# CY8C3866PVI_021 register map
File version: 0.1
CY8C38
Registers are 8-bit, read-write, no defined reset value unless marked. A register's access mark holds for its fields unless they carry their own. Offsets are from the block's base; lines under a group give offsets from that group; [hi:lo] are bit positions; {n}, {i} and the like mark numbered series; 'fields as' and 'values as' point back to an identical list; <NAME> marks a mode.

## Memory map
0x00004394 USBUART_1 size 0x1D0A — USBFS
0x000043A3 PWM_Rud size 0xB7C
0x000043A3 PWM_Bag size 0xB64
0x000043A3 PWM_Elv size 0xB70
0x000043A3 PWM_Thr size 0xB88
0x000049C8 I2C size 0x15
0x00006400 Counter_Thr size 0x92
0x00006402 Counter_Elv size 0x92
0x00006404 Counter_Rud size 0x92
0x00006406 Counter_Mod size 0x92
0x00006408 Counter_Bag size 0x92
0x00006504 Timer_Global size 0x94

## PWM_Rud
Base 0x000043A3
0x00 PWM_Rud_GLOBAL_ENABLE — PM.ACT.CFG
  [3:0] en_timer — Enable timer/counters.
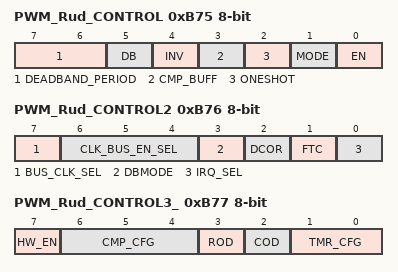
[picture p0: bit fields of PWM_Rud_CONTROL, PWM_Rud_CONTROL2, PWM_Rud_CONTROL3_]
0xB75 PWM_Rud_CONTROL — TMRx.CFG0
  [7:6] DEADBAND_PERIOD
  [5] DB — Deadband mode--Deadband phases phi1 and phi2 are outputted on CMP and TC output pins respectively.
    0=Timer (CMP and TC are output.); 1=Deadband (PHI1 (instead of CMP) and PHI2 (instead of TC) are output.)
  [4] INV — Invert sense of TIMEREN signal
  [3] CMP_BUFF — Buffer compare register. Compare register updates only on timer terminal count.
  [2] ONESHOT — Timer stops upon reaching stop condition defined by TMR_CFG bits. Can be restarted by asserting TIMER RESET or disabling and re-enabling block.
  [1] MODE ro — Mode. (0 = Timer; 1 = Comparator)
    0=Timer mode. CNT/CMP register holds timer count value.; 1=Comparator mode. CNT/CMP register holds comparator threshold value.
  [0] EN — Enables timer/comparator.
0xB76 PWM_Rud_CONTROL2 — TMRx.CFG1
  [7] BUS_CLK_SEL — Bus Clock selection.
  [6:4] CLK_BUS_EN_SEL — Digital Global Clock selection.
  [3] DBMODE — Deadband mode (asynchronous/synchronous). CMP output pin is also affected when not in deadband mode (CFG0.DEADBAND).
  [2] DCOR — Disable Clear on Read (DCOR) of Status Register SR0.
  [1] FTC — First Terminal Count (FTC). Setting this bit forces a single pulse on the TC pin when first enabled.
    0=Disable_FTC (Disable the single cycle pulse, which signifies the timer is starting.); 1=Enable_FTC (Enable the single cycle pulse, which signifies the timer is starting.)
  [0] IRQ_SEL — Irq selection. (0 = raw interrupts; 1 = status register interrupts)
0xB77 PWM_Rud_CONTROL3_ — TMRx.CFG2
  [7] HW_EN — When set Timer Enable controls counting.
  [6:4] CMP_CFG — Comparator configurations
    0=Equal (Compare Equal); 1=Less_than (Compare Less Than); 2=Less_than_or_equal (Compare Less Than or Equal .); 3=Greater (Compare Greater Than .); 4=Greater_than_or_equal (Compare Greater Than or Equal)
  [3] ROD — Reset On Disable (ROD). Resets internal state of output logic
  [2] COD — Clear On Disable (COD). Clears or gates outputs to zero.
  [1:0] TMR_CFG — Timer configuration (MODE = 0): 000 = Continuous; 001 = Pulsewidth; 010 = Period; 011 = Stop on IRQ
    0=Continuous (Timer runs while EN bit of CFG0 register is set to '1'.); 1=Pulsewidth (Timer runs from positive to negative edge of TIMEREN.); 2=Period (Timer runs from positive to positive edge of TIMEREN.); 3=Irq (Timer runs until IRQ.)
0xB79 PWM_Rud_PERIOD 16-bit — TMRx.PER0 - Assigned Period
0xB7B PWM_Rud_COMPARE 16-bit — TMRx.CNT_CMP0 - Assigned Compare Value

## Timer_Global
Base 0x00006504
0x00 Timer_Global_COUNTER 32-bit — UDB.A0 - Current Down Counter Value
0x20 Timer_Global_PERIOD 32-bit — UDB.D0 - Assigned Period
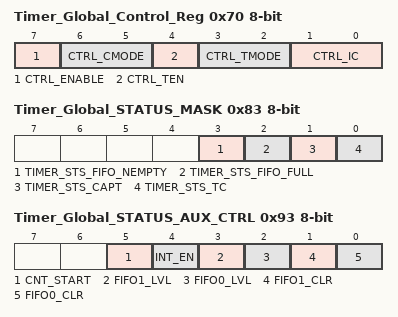
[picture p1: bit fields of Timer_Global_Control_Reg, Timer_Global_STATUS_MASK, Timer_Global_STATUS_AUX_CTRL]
0x70 Timer_Global_Control_Reg — UDB Control Register - Assigned Control Register Value
  [7] CTRL_ENABLE — Enable the Timer
  [6:5] CTRL_CMODE — Capture Mode
  [4] CTRL_TEN — Trigger Enable Bit
  [3:2] CTRL_TMODE — Trigger Mode
  [1:0] CTRL_IC — Interrupt Count
0x83 Timer_Global_STATUS_MASK — UDB Status bits Interrupt Mask Enable Register
  [3] TIMER_STS_FIFO_NEMPTY ro — FIFO Empty status
  [2] TIMER_STS_FIFO_FULL ro — FIFO Full Status
  [1] TIMER_STS_CAPT ro — Enables the Interrupt on Capture
  [0] TIMER_STS_TC ro — Enables the Interrupt on TC
0x93 Timer_Global_STATUS_AUX_CTRL — UDB Auxilliary Control Register
  [5] CNT_START — FIFO0 clear
    0=E_CNT_START0 (Disable counter); 1=E_CNT_START1 (Enable counter)
  [4] INT_EN
    0=E_INT_EN0 (Interrupt disabled); 1=E_INT_EN1 (Interrupt enabled)
  [3] FIFO1_LVL — FIFO level
    0=E_FIFO_LVL_0 (FIFO LVL: input mode: FIFO not full; output mode: FIFO not empty); 1=E_FIFO_LVL_1 (FIFO LVL: input mode: FIFO at least 1/2 empty; output mode: FIFO at least 1/2 full)
  [2] FIFO0_LVL — FIFO level
    values as FIFO1_LVL
  [1] FIFO1_CLR — FIFO1 clear
    0=E_FIFO_CLR_0 (Normal FIFO operation); 1=E_FIFO_CLR_1 (Clear FIFO state)
  [0] FIFO0_CLR — FIFO0 clear
    values as FIFO1_CLR
